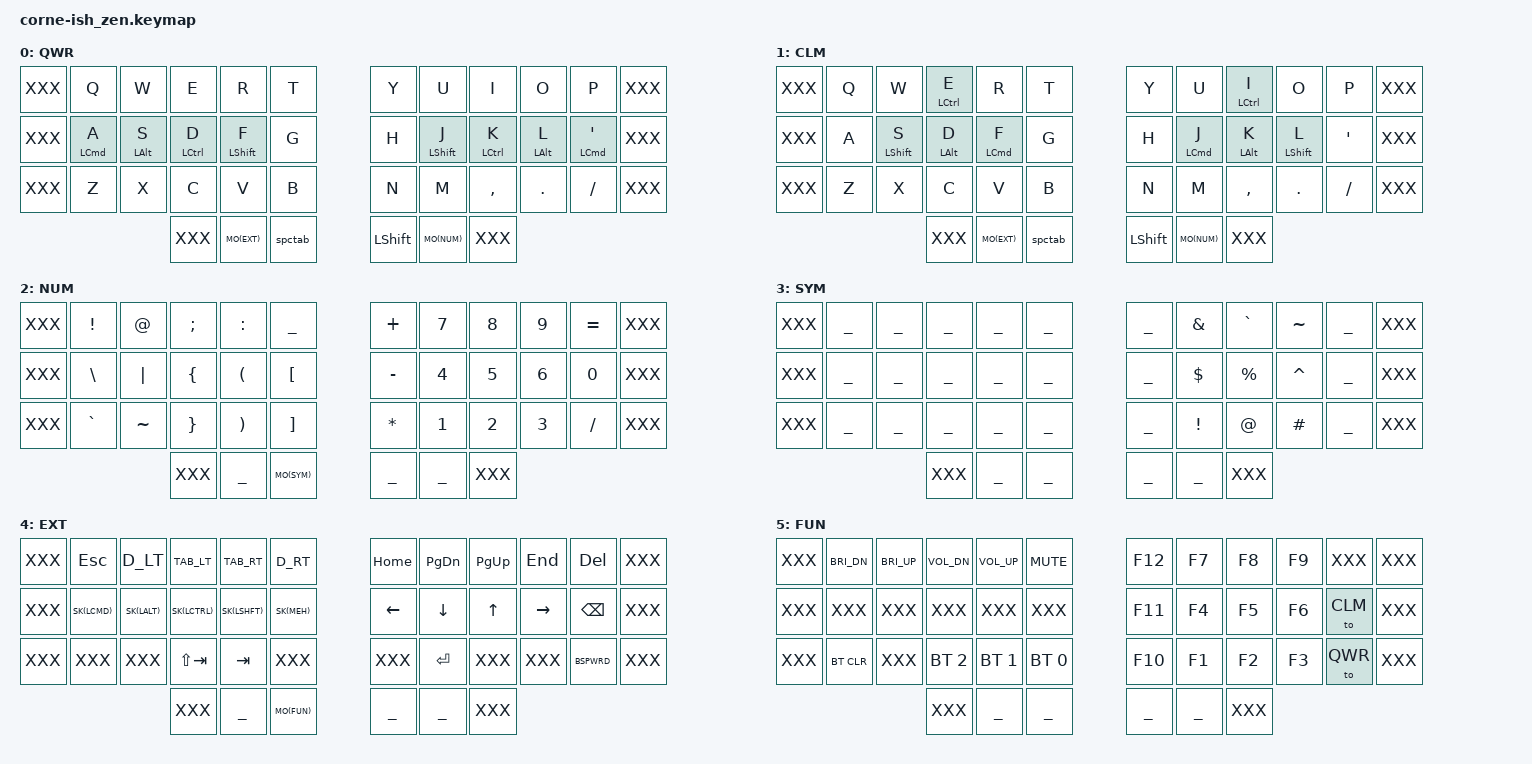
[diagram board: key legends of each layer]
#include <behaviors.dtsi>
#include <dt-bindings/zmk/keys.h>
#include <dt-bindings/zmk/bt.h>
#include "34keys.h"

&sk {
  release-after-ms = <STICKY_KEY_TIMEOUT>;
};

&caps_word {
  continue-list = <UNDERSCORE MINUS BACKSPACE N1 N2 N3 N4 N5 N6 N7 N8 N9 N0 KP_N1 KP_N2 KP_N3 KP_N4 KP_N5 KP_N6 KP_N7 KP_N8 KP_N9 KP_N0>;
};

&kscan0 {
  debounce-period = <14>;
};


/ {
  combos {
    #include "combos.dtsi"
  };

  behaviors {
    am: alpha_mods {
      compatible = "zmk,behavior-hold-tap";
      label = "alpha mods";
      #binding-cells = <2>;
      tapping-term-ms = <240>;
      quick-tap-ms = <180>;
      flavor = "tap-preferred";
      bindings = <&kp>, <&kp>;
      // compatible = "zmk,behavior-hold-tap";
      // label = "POSITIONAL_HOLD_TAP";
      // #binding-cells = <2>;
      // flavor = "tap-unless-interrupted";
      // tapping-term-ms = <100>;                        // <---[[produces tap if held longer than tapping-term-ms]]
      // quick-tap-ms = <200>;
      // bindings = <&kp>, <&kp>;
      // hold-trigger-key-positions = <5 6 7 8 9 10>;    // <---[[right-hand keys]]
    };

    // Easy alt-tab with alt+space thumb using mod-morphs
    spctab: space_tab {
      compatible = "zmk,behavior-mod-morph";
      label = "SPC_TAB";
      #binding-cells = <0>;
      bindings = <&kp SPACE>, <&kp TAB>;
      mods = <MOD_LALT>;
    };

    skq: sticky_key_quick_release {
      compatible = "zmk,behavior-sticky-key";
      label = "STICKY_KEY_QUICK_RELEASE";
      #binding-cells = <1>;
      bindings = <&kp>;
      quick-release;
      release-after-ms = <STICKY_KEY_TIMEOUT>;
    };

    // Use hold-tap to enable rolling sticky keys:
    // https://github.com/zmkfirmware/zmk/issues/829#issuecomment-979864774
    nk: not_so_sticky_key {
      compatible = "zmk,behavior-hold-tap";
      label = "NOT_SO_STICKY_KEY";
      #binding-cells = <2>;
      tapping_term_ms = <240>;
      flavor = "tap-preferred";
      bindings = <&kp>, <&sk>;
    };

    // A hold-tap that activates without delay (like `&mo`)
    mo_tap: mo_with_tap {
      compatible = "zmk,behavior-hold-tap";
      label = "MO_WITH_TAP";
      #binding-cells = <2>;
      tapping_term_ms = <0>;
      retro-tap;
      flavor = "hold-preferred";
      bindings = <&mo>, <&kp>;
    };

  };

  keymap {
    compatible = "zmk,keymap";

// Keyboard layout
// ╭─────────────┬─────────────┬─────────────┬─────────────┬─────────────┬─────────────╮   ╭─────────────┬─────────────┬─────────────┬─────────────┬─────────────┬─────────────╮
// ├─────────────┼─────────────┼─────────────┼─────────────┼─────────────┼─────────────┤   ├─────────────┼─────────────┼─────────────┼─────────────┼─────────────┼─────────────┤
// ├─────────────┼─────────────┼─────────────┼─────────────┼─────────────┼─────────────┤   ├─────────────┼─────────────┼─────────────┼─────────────┼─────────────┼─────────────┤
// ╰─────────────┴─────────────┴─────────────┼─────────────┼─────────────┼─────────────┤   ├─────────────┼─────────────┼─────────────┼─────────────┴─────────────┴─────────────╯
//                                           ╰─────────────┴─────────────┴─────────────╯   ╰─────────────┴─────────────┴─────────────╯

    qwerty_layer {
      label = "QWR";
      bindings = <
// ╭─────────────┬─────────────┬─────────────┬─────────────┬─────────────┬─────────────╮   ╭─────────────┬─────────────┬─────────────┬─────────────┬─────────────┬─────────────╮
     XXX           &kp Q         &kp W         &kp E         &kp R         &kp T             &kp Y         &kp U         &kp I         &kp O         &kp P         XXX
// ├─────────────┼─────────────┼─────────────┼─────────────┼─────────────┼─────────────┤   ├─────────────┼─────────────┼─────────────┼─────────────┼─────────────┼─────────────┤
     XXX           &am LCMD A    &am LALT S    &am LCTL D    &am LSHFT F   &kp G             &kp H         &am LSHFT J   &am LCTL K    &am LALT L    &am LCMD SQT  XXX
// ├─────────────┼─────────────┼─────────────┼─────────────┼─────────────┼─────────────┤   ├─────────────┼─────────────┼─────────────┼─────────────┼─────────────┼─────────────┤
     XXX           &kp Z         &kp X         &kp C         &kp V         &kp B             &kp N         &kp M         &kp COMMA     &kp DOT       &kp FSLH      XXX
// ╰─────────────┴─────────────┴─────────────┼─────────────┼─────────────┼─────────────┤   ├─────────────┼─────────────┼─────────────┼─────────────┴─────────────┴─────────────╯
                                               XXX           MO(EXT)       &spctab           &kp LSHFT     MO(NUM)       XXX
//                                           ╰─────────────┴─────────────┴─────────────╯   ╰─────────────┴─────────────┴─────────────╯
      >;
    };

    colemak_layer {
      label = "CLM";
      bindings = <
// ╭─────────────┬─────────────┬─────────────┬─────────────┬─────────────┬─────────────╮   ╭─────────────┬─────────────┬─────────────┬─────────────┬─────────────┬─────────────╮
     XXX           &kp Q         &kp W         &am LCTL E    &kp R         &kp T             &kp Y         &kp U         &am LCTL I    &kp O         &kp P         XXX
// ├─────────────┼─────────────┼─────────────┼─────────────┼─────────────┼─────────────┤   ├─────────────┼─────────────┼─────────────┼─────────────┼─────────────┼─────────────┤
     XXX           &kp A         &am LSHFT S   &am LALT D    &am LCMD F    &kp G             &kp H         &am LCMD J    &am LALT K    &am LSHFT L   &kp SQT       XXX
// ├─────────────┼─────────────┼─────────────┼─────────────┼─────────────┼─────────────┤   ├─────────────┼─────────────┼─────────────┼─────────────┼─────────────┼─────────────┤
     XXX           &kp Z         &kp X         &kp C         &kp V         &kp B             &kp N         &kp M         &kp COMMA     &kp DOT       &kp FSLH      XXX
// ╰─────────────┴─────────────┴─────────────┼─────────────┼─────────────┼─────────────┤   ├─────────────┼─────────────┼─────────────┼─────────────┴─────────────┴─────────────╯
                                               XXX           MO(EXT)       &spctab           &kp LSHFT     MO(NUM)       XXX
//                                           ╰─────────────┴─────────────┴─────────────╯   ╰─────────────┴─────────────┴─────────────╯
      >;
    };

    number_layer {
      label = "NUM";
      bindings = <
// ╭─────────────┬─────────────┬─────────────┬─────────────┬─────────────┬─────────────╮   ╭─────────────┬─────────────┬─────────────┬─────────────┬─────────────┬─────────────╮
     XXX           &kp EXCL      &kp AT        &kp SEMI      &kp COLON     &kp UNDER         &kp PLUS      &kp N7        &kp N8        &kp N9        &kp EQUAL     XXX
// ├─────────────┼─────────────┼─────────────┼─────────────┼─────────────┼─────────────┤   ├─────────────┼─────────────┼─────────────┼─────────────┼─────────────┼─────────────┤
     XXX           &kp BSLH      &kp PIPE      &kp LBRC      &kp LPAR      &kp LBKT          &kp MINUS     &kp N4        &kp N5        &kp N6        &kp N0        XXX
// ├─────────────┼─────────────┼─────────────┼─────────────┼─────────────┼─────────────┤   ├─────────────┼─────────────┼─────────────┼─────────────┼─────────────┼─────────────┤
     XXX           &kp GRAVE     &kp TILDE     &kp RBRC      &kp RPAR      &kp RBKT          &kp ASTRK     &kp N1        &kp N2        &kp N3        &kp FSLH      XXX
// ╰─────────────┴─────────────┴─────────────┼─────────────┼─────────────┼─────────────┤   ├─────────────┼─────────────┼─────────────┼─────────────┴─────────────┴─────────────╯
                                          	   XXX           ___           MO(SYM)           ___           ___           XXX
//                                           ╰─────────────┴─────────────┴─────────────╯   ╰─────────────┴─────────────┴─────────────╯
      >;
    };

    symbol_layer {
      label = "SYM";
      bindings = <
// ╭─────────────┬─────────────┬─────────────┬─────────────┬─────────────┬─────────────╮   ╭─────────────┬─────────────┬─────────────┬─────────────┬─────────────┬─────────────╮
     XXX           ___           ___           ___           ___           ___               ___           &kp AMPS      &kp GRAVE     &kp TILDE     ___           XXX
// ├─────────────┼─────────────┼─────────────┼─────────────┼─────────────┼─────────────┤   ├─────────────┼─────────────┼─────────────┼─────────────┼─────────────┼─────────────┤
     XXX           ___           ___           ___           ___           ___               ___           &kp DLLR      &kp PRCNT     &kp CARET     ___           XXX
// ├─────────────┼─────────────┼─────────────┼─────────────┼─────────────┼─────────────┤   ├─────────────┼─────────────┼─────────────┼─────────────┼─────────────┼─────────────┤
     XXX           ___           ___           ___           ___           ___               ___           &kp EXCL      &kp AT        &kp HASH      ___           XXX
// ╰─────────────┴─────────────┴─────────────┼─────────────┼─────────────┼─────────────┤   ├─────────────┼─────────────┼─────────────┼─────────────┴─────────────┴─────────────╯
                                               XXX           ___           ___               ___           ___           XXX
//                                           ╰─────────────┴─────────────┴─────────────╯   ╰─────────────┴─────────────┴─────────────╯
      >;
    };

    extend_layer {
      label = "EXT";
      bindings = <
// ╭─────────────┬─────────────┬─────────────┬─────────────┬─────────────┬─────────────╮   ╭─────────────┬─────────────┬─────────────┬─────────────┬─────────────┬─────────────╮
     XXX           &kp ESC       &kp D_LT      &kp TAB_LT    &kp TAB_RT    &kp D_RT          &kp HOME      &kp PG_DN     &kp PG_UP     &kp END       &kp DEL       XXX
// ├─────────────┼─────────────┼─────────────┼─────────────┼─────────────┼─────────────┤   ├─────────────┼─────────────┼─────────────┼─────────────┼─────────────┼─────────────┤
     XXX           SK(LCMD)      SK(LALT)      SK(LCTRL)     SK(LSHFT)     SK(MEH)           &kp LEFT      &kp DOWN      &kp UP        &kp RIGHT     &kp BSPC      XXX
// ├─────────────┼─────────────┼─────────────┼─────────────┼─────────────┼─────────────┤   ├─────────────┼─────────────┼─────────────┼─────────────┼─────────────┼─────────────┤
     XXX           XXX           XXX           &kp LS(TAB)   &kp TAB       XXX               XXX           &kp RET       XXX           XXX           &kp BSPWRD    XXX
// ╰─────────────┴─────────────┴─────────────┼─────────────┼─────────────┼─────────────┤   ├─────────────┼─────────────┼─────────────┼─────────────┴─────────────┴─────────────╯
                                               XXX           ___           MO(FUN)           ___           ___           XXX
//                                           ╰─────────────┴─────────────┴─────────────╯   ╰─────────────┴─────────────┴─────────────╯
      >;
    };

    function_layer {
      label = "FUN";
      bindings = <
// ╭─────────────┬─────────────┬─────────────┬─────────────┬─────────────┬─────────────╮   ╭─────────────┬─────────────┬─────────────┬─────────────┬─────────────┬─────────────╮
     XXX           &kp C_BRI_DN  &kp C_BRI_UP  &kp C_VOL_DN  &kp C_VOL_UP  &kp C_MUTE        &kp F12       &kp F7        &kp F8        &kp F9        XXX           XXX
// ├─────────────┼─────────────┼─────────────┼─────────────┼─────────────┼─────────────┤   ├─────────────┼─────────────┼─────────────┼─────────────┼─────────────┼─────────────┤
     XXX           XXX           XXX           XXX           XXX           XXX               &kp F11       &kp F4        &kp F5        &kp F6        &to CLM       XXX
// ├─────────────┼─────────────┼─────────────┼─────────────┼─────────────┼─────────────┤   ├─────────────┼─────────────┼─────────────┼─────────────┼─────────────┼─────────────┤
     XXX           &bt BT_CLR    XXX           &bt BT_SEL 2  &bt BT_SEL 1  &bt BT_SEL 0      &kp F10       &kp F1        &kp F2        &kp F3        &to QWR       XXX
// ╰─────────────┴─────────────┴─────────────┼─────────────┼─────────────┼─────────────┤   ├─────────────┼─────────────┼─────────────┼─────────────┴─────────────┴─────────────╯
                              	               XXX           ___           ___               ___           ___           XXX
//                                           ╰─────────────┴─────────────┴─────────────╯   ╰─────────────┴─────────────┴─────────────╯
      >;
    };

  };
};
